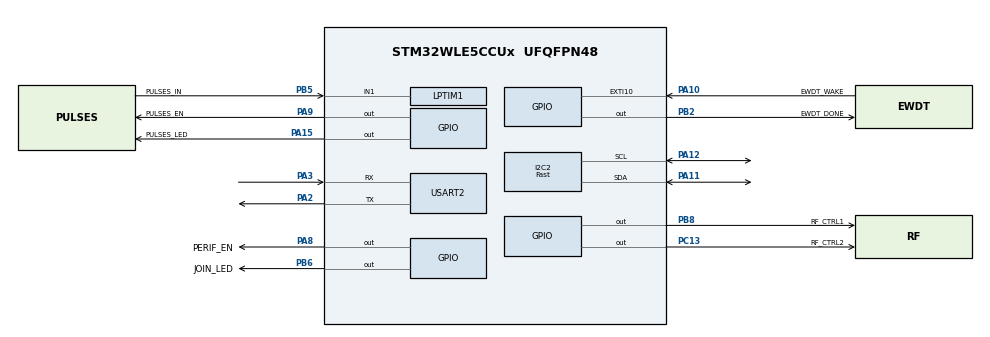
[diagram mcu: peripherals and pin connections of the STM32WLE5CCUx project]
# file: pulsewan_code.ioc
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ADC.NbrOfConversion=1
ADC.SelectedChannel=ADC_CHANNEL_VREFINT
Dma.Request0=USART2_TX
Dma.USART2_TX.0.Direction=DMA_MEMORY_TO_PERIPH
Dma.USART2_TX.0.EventEnable=DISABLE
Dma.USART2_TX.0.Instance=DMA1_Channel1
Dma.USART2_TX.0.MemDataAlignment=DMA_MDATAALIGN_BYTE
Dma.USART2_TX.0.MemInc=DMA_MINC_ENABLE
Dma.USART2_TX.0.Mode=DMA_NORMAL
Dma.USART2_TX.0.PeriphDataAlignment=DMA_PDATAALIGN_BYTE
Dma.USART2_TX.0.PeriphInc=DMA_PINC_DISABLE
Dma.USART2_TX.0.Polarity=HAL_DMAMUX_REQ_GEN_RISING
Dma.USART2_TX.0.Priority=DMA_PRIORITY_LOW
Dma.USART2_TX.0.RequestNumber=1
Dma.USART2_TX.0.SignalID=NONE
Dma.USART2_TX.0.SyncEnable=DISABLE
Dma.USART2_TX.0.SyncPolarity=HAL_DMAMUX_SYNC_NO_EVENT
Dma.USART2_TX.0.SyncRequestNumber=1
Dma.USART2_TX.0.SyncSignalID=NONE
I2C2.Analog_Filter=I2C_ANALOGFILTER_ENABLE
I2C2.I2C_Speed_Mode=I2C_Fast
I2C2.Timing=0x2010091A
LORAWAN.CONTEXT_MANAGEMENT_ENABLED=true
LORAWAN.LORAWAN_DATA_DISTRIB_MGT=false
LORAWAN.LORAWAN_DEFAULT_CONFIRMED_MSG_STATE=LORAMAC_HANDLER_CONFIRMED_MSG
LORAWAN.LORAWAN_FORCE_REJOIN_AT_BOOT=true
LORAWAN.LORAWAN_TIMER_OR_BUTTON=TX_ON_EVENT
LORAWAN.REGION_AU915=true
LORAWAN.REGION_EU868=false
LORAWAN.REGION_US915=false
LORAWAN.SUBGHZ_APPLICATION=LORA_END_NODE
LORAWAN.TX_RFO_CONFIG=RBI_CONF_RFO_HP
LoRaWAN.BSP.number=3
LoRaWAN0.BSP.STBoard=false
LoRaWAN0.BSP.api=Unknown
LoRaWAN0.BSP.condition=\!SEM_LORA_USER_APPLICATION | SEM_LORA_USE_ADC
LoRaWAN0.BSP.instance=ADC
LoRaWAN0.BSP.ip=ADC
LoRaWAN0.BSP.mode=Vrefint Channel
LoRaWAN0.BSP.name=ADC
LoRaWAN0.BSP.solution=ADC
LoRaWAN1.BSP.STBoard=false
LoRaWAN1.BSP.api=Unknown
LoRaWAN1.BSP.condition=\!SEM_LORA_USER_APPLICATION | SEM_LORA_USE_RTC
LoRaWAN1.BSP.instance=RTC
LoRaWAN1.BSP.ip=RTC
LoRaWAN1.BSP.mode=RTC Enabled
LoRaWAN1.BSP.name=RTC
LoRaWAN1.BSP.solution=RTC
LoRaWAN2.BSP.STBoard=false
LoRaWAN2.BSP.api=Unknown
LoRaWAN2.BSP.condition=SEM_LORA_END_NODE  | SEM_LORA_USE_UART
LoRaWAN2.BSP.instance=USART2
LoRaWAN2.BSP.ip=(LPU|US)ART
LoRaWAN2.BSP.mode=Asynchronous
LoRaWAN2.BSP.name=USART
LoRaWAN2.BSP.solution=USART2
Mcu.Family=STM32WL
Mcu.Name=STM32WLE5CCUx
Mcu.Package=UFQFPN48
Mcu.UserConstants=RTC_PREDIV_A,((1<<(15-RTC_N_PREDIV_S))-1);RTC_N_PREDIV_S,10;RTC_PREDIV_S,((1<<RTC_N_PREDIV_S)-1)
NVIC.DMA1_Channel1_IRQn=true\:0\:0\:false\:false\:true\:false\:true\:true
NVIC.EXTI15_10_IRQn=true\:0\:0\:false\:false\:true\:true\:true\:true
NVIC.PriorityGroup=NVIC_PRIORITYGROUP_4
NVIC.RTC_Alarm_IRQn=true\:0\:0\:false\:false\:true\:true\:true\:true
NVIC.SUBGHZ_Radio_IRQn=true\:0\:0\:false\:false\:true\:true\:true\:true
NVIC.TAMP_STAMP_LSECSS_SSRU_IRQn=true\:0\:0\:false\:false\:true\:true\:true\:true
NVIC.USART2_IRQn=true\:0\:0\:false\:false\:true\:true\:true\:true
OSC_IN.Mode=HSE-External-Oscillator
OSC_IN.Signal=RCC_OSC_IN
OSC_OUT.Mode=HSE-External-Oscillator
OSC_OUT.Signal=RCC_OSC_OUT
PA10.GPIO_Label=EWDT_WAKE
PA10.GPIO_PuPd=GPIO_PULLUP
PA10.Signal=GPXTI10
PA11.Mode=I2C
PA11.Signal=I2C2_SDA
PA12.Mode=I2C
PA12.Signal=I2C2_SCL
PA15.GPIO_Label=PULSES_LED
PA15.Signal=GPIO_Output
PA2.GPIO_PuPd=GPIO_NOPULL
PA2.Mode=Asynchronous
PA2.Signal=USART2_TX
PA3.GPIO_PuPd=GPIO_PULLUP
PA3.Mode=Asynchronous
PA3.Signal=USART2_RX
PA8.GPIO_Label=PERIF_EN
PA8.PinState=GPIO_PIN_SET
PA8.Signal=GPIO_Output
PA9.GPIO_Label=PULSES_EN
PA9.PinState=GPIO_PIN_SET
PA9.Signal=GPIO_Output
PB2.GPIO_Label=EWDT_DONE
PB2.Signal=GPIO_Output
PB5.GPIO_Label=PULSES_IN
PB5.Mode=Counts_external_clock_with_synchro_01_occur1
PB5.Signal=LPTIM1_IN1
PB6.GPIO_Label=JOIN_LED
PB6.Signal=GPIO_Output
PB8.GPIO_Label=RF_CTRL1
PB8.Signal=GPIO_Output
PC13.GPIO_Label=RF_CTRL2
PC13.Signal=GPIO_Output
PC14-OSC32_IN.Mode=LSE-External-Oscillator
PC14-OSC32_IN.Signal=RCC_OSC32_IN
PC15-OSC32_OUT.Mode=LSE-External-Oscillator
PC15-OSC32_OUT.Signal=RCC_OSC32_OUT
ProjectManager.HeapSize=0x200
ProjectManager.StackSize=0x400
ProjectManager.TargetToolchain=STM32CubeIDE
RCC.AHBFreq_Value=48000000
RCC.APB1Freq_Value=48000000
RCC.APB1TimFreq_Value=48000000
RCC.APB2Freq_Value=48000000
RCC.APB2TimFreq_Value=48000000
RCC.APB3Freq_Value=48000000
RCC.CortexFreq_Value=48000000
RCC.HCLKFreq_Value=48000000
RCC.HSE_VALUE=32000000
RCC.HSI_VALUE=16000000
RCC.I2C2CLockSelection=RCC_I2C2CLKSOURCE_SYSCLK
RCC.LPTIM1CLockSelection=RCC_LPTIM1CLKSOURCE_LSE
RCC.LSE_VALUE=32768
RCC.MSIClockRange=RCC_MSIRANGE_11
RCC.RTCClockSelection=RCC_RTCCLKSOURCE_LSE
RCC.SYSCLKFreq_VALUE=48000000
RCC.VCOOutputFreq_Value=384000000
RTC.Alarm-Alarm\ A=RTC_ALARM_A
RTC.AsynchPrediv=RTC_PREDIV_A
RTC.BinMode=RTC_BINARY_ONLY
USART2.VirtualMode-Asynchronous=VM_ASYNC
VP_ADC_Vref_Input.Mode=IN-Vrefint
VP_ADV_TRACE_VS_ADV_TRACE.Mode=ADV_TRACE_Enabled
VP_LORAWAN_VS_LoRaWAN.Mode=LoRaWAN_Enabled
VP_MISC_VS_MISC.Mode=MISC_Enabled
VP_RTC_VS_RTC_Activate.Mode=RTC_Enabled
VP_RTC_VS_RTC_Alarm_A_Intern.Mode=Alarm A
VP_RTC_VS_RTC_Calendar.Mode=RTC_Calendar
VP_SEQUENCER_VS_SEQUENCER.Mode=SEQUENCER_Enabled
VP_SUBGHZ_VS_SUBGHZ.Mode=SUBGHZ_Activate
VP_TIMER_VS_TIMER.Mode=TIMER_Enabled
VP_TINY_LPM_VS_TINY_LPM.Mode=TINY_LPM_Enabled
board=custom

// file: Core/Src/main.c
/* USER CODE BEGIN Header */
/**
  ******************************************************************************
  * @file           : main.c
  * @brief          : Main program body
  ******************************************************************************
  * @attention
  *
  * Copyright (c) 2023 STMicroelectronics.
  * All rights reserved.
  *
  * This software is licensed under terms that can be found in the LICENSE file
  * in the root directory of this software component.
  * If no LICENSE file comes with this software, it is provided AS-IS.
  *
  ******************************************************************************
  */
/* USER CODE END Header */
#include "main.h"
#include "adc.h"
#include "dma.h"
#include "i2c.h"
#include "app_lorawan.h"
#include "lptim.h"
#include "rtc.h"
#include "usart.h"
#include "gpio.h"

/* USER CODE BEGIN Includes */
#include "shtc3.h"
/* USER CODE END Includes */

void SystemClock_Config(void);

int main(void)
{

  /* MCU Configuration--------------------------------------------------------*/

  /* Reset of all peripherals, Initializes the Flash interface and the Systick. */
  HAL_Init();

  /* Configure the system clock */
  SystemClock_Config();

  /* Initialize all configured peripherals */
  MX_GPIO_Init();
  MX_DMA_Init();
  MX_ADC_Init();
  MX_RTC_Init();
  MX_LoRaWAN_Init();
  MX_LPTIM1_Init();
  MX_USART2_UART_Init();
  MX_I2C2_Init();
  /* USER CODE BEGIN 2 */
  if (HAL_LPTIM_Counter_Start(&hlptim1, 0xFFFF) != HAL_OK) {
  	Error_Handler();
  }

  shtc3_sleep(&hi2c2);
  /* USER CODE END 2 */

  /* Infinite loop */
  while (1)
  {
    MX_LoRaWAN_Process();

  }
}

void SystemClock_Config(void)
{
  RCC_OscInitTypeDef RCC_OscInitStruct = {0};
  RCC_ClkInitTypeDef RCC_ClkInitStruct = {0};

  /** Configure LSE Drive Capability
  */
  HAL_PWR_EnableBkUpAccess();
  __HAL_RCC_LSEDRIVE_CONFIG(RCC_LSEDRIVE_LOW);

  /** Configure the main internal regulator output voltage
  */
  __HAL_PWR_VOLTAGESCALING_CONFIG(PWR_REGULATOR_VOLTAGE_SCALE1);

  /** Initializes the CPU, AHB and APB buses clocks
  */
  RCC_OscInitStruct.OscillatorType = RCC_OSCILLATORTYPE_LSE|RCC_OSCILLATORTYPE_MSI;
  RCC_OscInitStruct.LSEState = RCC_LSE_ON;
  RCC_OscInitStruct.MSIState = RCC_MSI_ON;
  RCC_OscInitStruct.MSICalibrationValue = RCC_MSICALIBRATION_DEFAULT;
  RCC_OscInitStruct.MSIClockRange = RCC_MSIRANGE_11;
  RCC_OscInitStruct.PLL.PLLState = RCC_PLL_NONE;
  if (HAL_RCC_OscConfig(&RCC_OscInitStruct) != HAL_OK)
  {
    Error_Handler();
  }

  /** Configure the SYSCLKSource, HCLK, PCLK1 and PCLK2 clocks dividers
  */
  RCC_ClkInitStruct.ClockType = RCC_CLOCKTYPE_HCLK3|RCC_CLOCKTYPE_HCLK
                              |RCC_CLOCKTYPE_SYSCLK|RCC_CLOCKTYPE_PCLK1
                              |RCC_CLOCKTYPE_PCLK2;
  RCC_ClkInitStruct.SYSCLKSource = RCC_SYSCLKSOURCE_MSI;
  RCC_ClkInitStruct.AHBCLKDivider = RCC_SYSCLK_DIV1;
  RCC_ClkInitStruct.APB1CLKDivider = RCC_HCLK_DIV1;
  RCC_ClkInitStruct.APB2CLKDivider = RCC_HCLK_DIV1;
  RCC_ClkInitStruct.AHBCLK3Divider = RCC_SYSCLK_DIV1;

  if (HAL_RCC_ClockConfig(&RCC_ClkInitStruct, FLASH_LATENCY_2) != HAL_OK)
  {
    Error_Handler();
  }
}

void Error_Handler(void)
{
  __disable_irq();
  while (1)
  {
  }
}
